# ADuCM302x register map
Vendor: Analog Devices; Series: ADuCM302x; File version: 1p0
ARM Cortex-M3 Microcontroller based device
CPU: CM3 r0p1, little endian, no MPU, no FPU, 3 interrupt priority bits
Registers are 32-bit, read-write, reset 0x0 unless marked. A register's access mark holds for its fields unless they carry their own. Offsets are from the block's base; lines under a group give offsets from that group; [hi:lo] are bit positions; {n}, {i} and the like mark numbered series; 'fields as' and 'values as' point back to an identical list; <NAME> marks a mode.

## Memory map
0x40000000 TMR0 size 0x40 — General Purpose Timer
0x40000400 TMR1 size 0x40
0x40000800 TMR2 size 0x40
0x40001000 RTC0 size 0x100 — Real-Time Clock
0x40001400 RTC1 size 0x100
0x40002000 SYS size 0x80 — System Identification and Debug Enable
0x40002C00 WDT0 size 0x20 — Watchdog Timer
0x40003000 I2C0 size 0x80 — I2C Master/Slave
0x40004000 SPI0 size 0x100 — Serial Peripheral Interface
0x40004400 SPI1 size 0x100
0x40005000 UART0 size 0x100
0x40005C00 BEEP0 size 0x100 — Beeper Driver
0x40007000 ADC0 size 0x400
0x40010000 DMA0 size 0x1000 — DMA
0x40018000 FLCC0 size 0x100 — Flash Controller
0x40018058 FLCC0_CACHE size 0x100 — Cache Controller
0x40020000 GPIO0 size 0x4000
0x40020040 GPIO1 size 0x4000
0x40020080 GPIO2 size 0x4000
0x40024000 SPI2 size 0x100
0x40038000 SPORT0 size 0x100 — Serial Port
0x40040000 CRC0 size 0x100 — CRC Accelerator
0x40040400 RNG0 size 0x100 — Random Number Generator
0x40044000 CRYPT0 size 0x200 — Register Map for the Crypto Block
0x4004C000 PMG0 size 0x4000 — Power Management
0x4004C080 XINT0 size 0x4000 — External interrupt configuration
0x4004C100 CLKG0_OSC size 0x4000 — Clocking
0x4004C200 PMG0_TST size 0x4000 — Power Management
0x4004C300 CLKG0_CLK size 0x4000 — Clocking
0x4004C800 BUSM0 size 0x4000 — Bus matrix
0xE000E000 NVIC0 size 0x1000 — Cortex-M3 Interrupt Controller

## Interrupts
0 RTC1_EVT (RTC1) — Event
1 XINT_EVT0 (XINT0) — External Wakeup Interrupt n
2 XINT_EVT1 (XINT0) — External Wakeup Interrupt n
3 XINT_EVT2 (XINT0) — External Wakeup Interrupt n
4 XINT_EVT3 (XINT0) — External Wakeup Interrupt n
5 WDT_EXP (WDT0) — Expiration
6 PMG0_VREG_OVR (PMG0) — Voltage Regulator (VREG) Overvoltage
7 PMG0_BATT_RANGE (PMG0) — Battery Voltage (VBAT) Out of Range
8 RTC0_EVT (RTC0) — Event
9 SYS_GPIO_INTA (SYS) — GPIO Interrupt A
10 SYS_GPIO_INTB (SYS) — GPIO Interrupt B
11 TMR0_EVT (TMR0) — Event
12 TMR1_EVT (TMR1) — Event
14 UART_EVT (UART0) — Event
15 SPI0_EVT (SPI0) — Event
16 SPI2_EVT (SPI2) — Event
17 I2C_SLV_EVT (I2C0) — Slave Event
18 I2C_MST_EVT (I2C0) — Master Event
19 DMA_CHAN_ERR (DMA0) — Channel Error
{n+20} DMA0_CH{n}_DONE (DMA0) (n=0..15) — Channel {n} Done
36 SPORT_A_EVT (SPORT0) — Channel A Event
37 SPORT_B_EVT (SPORT0) — Channel B Event
38 CRYPT_EVT (CRYPT0) — Event
39 DMA0_CH24_DONE (DMA0) — Channel 24 Done
40 TMR2_EVT (TMR2) — Event
41 CLKG_XTAL_OSC_EVT (CLKG0_OSC) — Crystal Oscillator Event
42 SPI1_EVT (SPI1) — Event
43 CLKG_PLL_EVT (CLKG0_OSC) — PLL Event
44 RNG0_EVT (RNG0) — Event
45 BEEP_EVT (BEEP0) — Event
46 ADC0_EVT (ADC0) — Event
{n+40} DMA0_CH{n}_DONE (DMA0) (n=16..23) — Channel {n} Done

## TMR0 — General Purpose Timer
Base 0x40000000
Same registers: TMR1 0x40000400, TMR2 0x40000800
0x00 LOAD 16-bit — 16-bit Load Value
  [15:0] VALUE range 0x00000000..0x0000FFFF — Load Value
0x04 CURCNT 16-bit — 16-bit Timer Value
  [15:0] VALUE ro — Current Count
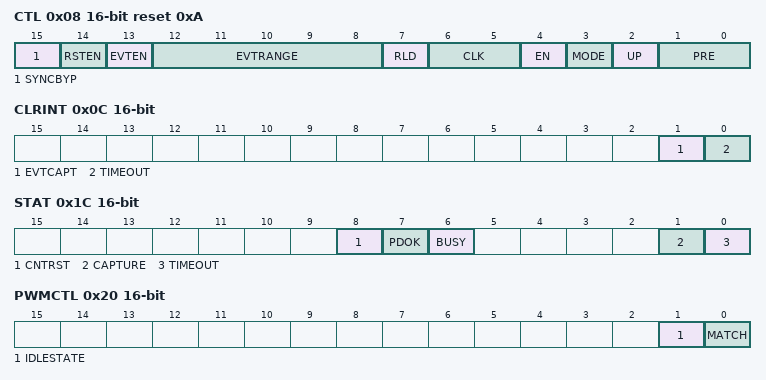
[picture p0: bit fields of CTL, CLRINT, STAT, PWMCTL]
0x08 CTL 16-bit reset 0xA — Control
  [15] SYNCBYP — Synchronization Bypass
  [14] RSTEN range 0x00000000..0x00000001 — Counter and Prescale Reset Enable
  [13] EVTEN — Event Select
  [12:8] EVTRANGE range 0x00000000..0x0000001F — Event Select Range
  [7] RLD — Reload Control
  [6:5] CLK — Clock Select
  [4] EN — Timer Enable
  [3] MODE — Timer Mode
  [2] UP — Count up
  [1:0] PRE — Prescaler
0x0C CLRINT 16-bit — Clear Interrupt
  [1] EVTCAPT wo — Clear Captured Event Interrupt
  [0] TIMEOUT wo — Clear Timeout Interrupt
0x10 CAPTURE 16-bit
  [15:0] VALUE ro — 16-bit Captured Value
0x14 ALOAD 16-bit — 16-bit Load Value, Asynchronous
  [15:0] VALUE range 0x00000000..0x0000FFFF — Load Value, Asynchronous
0x18 ACURCNT 16-bit — 16-bit Timer Value, Asynchronous
  [15:0] VALUE ro — Counter Value
0x1C STAT 16-bit — Status
  [8] CNTRST ro — Counter Reset Occurring
  [7] PDOK ro — Clear Interrupt Register Synchronization
  [6] BUSY ro — Timer Busy
  [1] CAPTURE ro — Capture Event Pending
  [0] TIMEOUT ro — Timeout Event Occurred
0x20 PWMCTL 16-bit — PWM Control Register
  [1] IDLESTATE — PWM Idle State
    0=IDLE_LOW (PWM idles low); 1=IDLE_HIGH (PWM idles high)
  [0] MATCH — PWM Match Enabled
    0=PWM_TOGGLE (PWM in toggle mode); 1=PWM_MATCH (PWM in match mode)
0x24 PWMMATCH 16-bit — PWM Match Value
  [15:0] VALUE range 0x00000000..0x0000FFFF

## Licence text in the file
ARM Limited (ARM) is supplying this software for use with Cortex-M processor based microcontroller, but can be equally used for other suitable processor architectures. This file can be freely distributed. Modifications to this file shall be clearly marked. THIS SOFTWARE IS PROVIDED "AS IS". NO WARRANTIES, WHETHER EXPRESS, IMPLIED OR STATUTORY, INCLUDING, BUT NOT LIMITED TO, IMPLIED WARRANTIES OF MERCHANTABILITY AND FITNESS FOR A PARTICULAR PURPOSE APPLY TO THIS SOFTWARE. ARM SHALL NOT, IN ANY CIRCUMSTANCES, BE LIABLE FOR SPECIAL, INCIDENTAL, OR CONSEQUENTIAL DAMAGES, FOR ANY REASON WHATSOEVER.

## Notices in the file
Copyright (c) 2014-2017 Analog Devices, Inc.  All Rights Reserved.
This software is proprietary and confidential to Analog Devices, Inc.
and its licensors.
